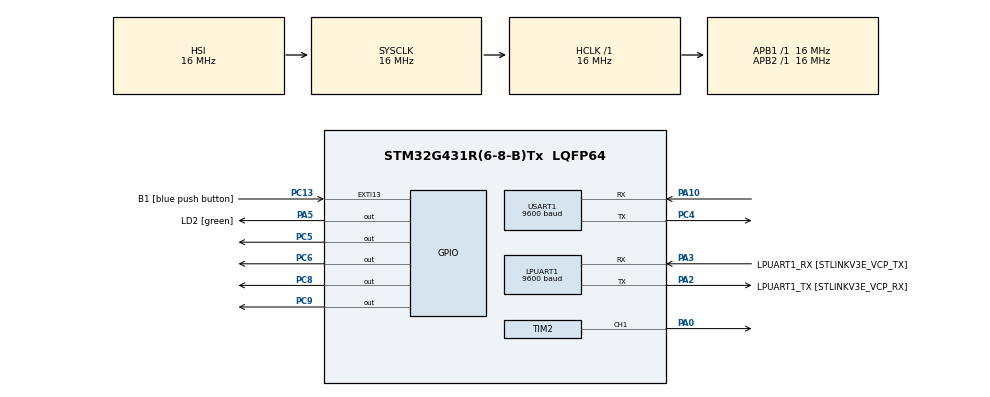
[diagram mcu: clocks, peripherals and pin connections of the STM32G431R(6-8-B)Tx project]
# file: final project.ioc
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LPUART1.BaudRate=9600
LPUART1.WordLength=UART_WORDLENGTH_8B
Mcu.Family=STM32G4
Mcu.Name=STM32G431R(6-8-B)Tx
Mcu.Package=LQFP64
NVIC.PriorityGroup=NVIC_PRIORITYGROUP_4
PA0.Signal=S_TIM2_CH1
PA10.Mode=Asynchronous
PA10.Signal=USART1_RX
PA13.GPIO_Label=T_SWDIO
PA13.Mode=Serial_Wire
PA13.Signal=SYS_JTMS-SWDIO
PA14.GPIO_Label=T_SWCLK
PA14.Mode=Serial_Wire
PA14.Signal=SYS_JTCK-SWCLK
PA2.GPIO_Label=LPUART1_TX [STLINKV3E_VCP_RX]
PA2.Mode=Asynchronous
PA2.Signal=LPUART1_TX
PA3.GPIO_Label=LPUART1_RX [STLINKV3E_VCP_TX]
PA3.Mode=Asynchronous
PA3.Signal=LPUART1_RX
PA5.GPIO_Label=LD2 [green]
PA5.Signal=GPIO_Output
PB3.GPIO_Label=T_SWO
PB3.Signal=SYS_JTDO-SWO
PC13.GPIO_Label=B1 [blue push button]
PC13.Signal=GPXTI13
PC14-OSC32_IN.Mode=LSE-External-Oscillator
PC14-OSC32_IN.Signal=RCC_OSC32_IN
PC15-OSC32_OUT.Mode=LSE-External-Oscillator
PC15-OSC32_OUT.Signal=RCC_OSC32_OUT
PC4.Mode=Asynchronous
PC4.Signal=USART1_TX
PC5.Signal=GPIO_Output
PC6.Signal=GPIO_Output
PC8.Signal=GPIO_Output
PC9.Signal=GPIO_Output
PF0-OSC_IN.Mode=HSE-External-Oscillator
PF0-OSC_IN.Signal=RCC_OSC_IN
PF1-OSC_OUT.Mode=HSE-External-Oscillator
PF1-OSC_OUT.Signal=RCC_OSC_OUT
ProjectManager.HeapSize=0x200
ProjectManager.StackSize=0x400
ProjectManager.TargetToolchain=STM32CubeIDE
RCC.ADC12Freq_Value=16000000
RCC.AHBFreq_Value=16000000
RCC.APB1Freq_Value=16000000
RCC.APB1TimFreq_Value=16000000
RCC.APB2Freq_Value=16000000
RCC.APB2TimFreq_Value=16000000
RCC.CortexFreq_Value=16000000
RCC.EXTERNAL_CLOCK_VALUE=12288000
RCC.HCLKFreq_Value=16000000
RCC.HSE_VALUE=24000000
RCC.HSI48_VALUE=48000000
RCC.HSI_VALUE=16000000
RCC.PLLM=RCC_PLLM_DIV4
RCC.PLLN=85
RCC.RTCClockSelection=RCC_RTCCLKSOURCE_LSE
RCC.SYSCLKFreq_VALUE=16000000
RCC.USBFreq_Value=170000000
RCC.VCOOutputFreq_Value=340000000
SH.S_TIM2_CH1.0=TIM2_CH1,PWM Generation1 CH1
TIM2.Channel-PWM\ Generation1\ CH1=TIM_CHANNEL_1
TIM2.PeriodNoDither=100
TIM2.Prescaler=16000-1
USART1.BaudRate=9600
USART1.VirtualMode-Asynchronous=VM_ASYNC
VP_SYS_VS_DBSignals.Mode=DisableDeadBatterySignals
VP_TIM2_VS_ClockSourceINT.Mode=Internal
board=NUCLEO-G431RB

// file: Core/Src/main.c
/* USER CODE BEGIN Header */
/**
  ******************************************************************************
  * @file           : main.c
  * @brief          : Main program body
  ******************************************************************************
  * @attention
  *
  * Copyright (c) 2023 STMicroelectronics.
  * All rights reserved.
  *
  * This software is licensed under terms that can be found in the LICENSE file
  * in the root directory of this software component.
  * If no LICENSE file comes with this software, it is provided AS-IS.
  *
  ******************************************************************************
  */
/* USER CODE END Header */
#include "main.h"

UART_HandleTypeDef hlpuart1;
UART_HandleTypeDef huart1;

TIM_HandleTypeDef htim2;

void SystemClock_Config(void);
static void MX_GPIO_Init(void);
static void MX_LPUART1_UART_Init(void);
static void MX_TIM2_Init(void);
static void MX_USART1_UART_Init(void);

int main(void)
{
  /* USER CODE BEGIN 1 */
char c;
  /* USER CODE END 1 */

  /* MCU Configuration--------------------------------------------------------*/

  /* Reset of all peripherals, Initializes the Flash interface and the Systick. */
  HAL_Init();

  /* Configure the system clock */
  SystemClock_Config();

  /* Initialize all configured peripherals */
  MX_GPIO_Init();
  MX_LPUART1_UART_Init();
  MX_TIM2_Init();
  MX_USART1_UART_Init();

  /* Infinite loop */
  while (1)
  {
	  HAL_UART_Receive(&huart1,&c,1,2000);
	  HAL_TIM_PWM_Start(&htim2,TIM_CHANNEL_1);
	  switch (c)
	  {

/////////////////////////////////////////////////////MOTOR 1////////////////////////////////////////////////
	  case 'A':
	  HAL_GPIO_WritePin(GPIOC,GPIO_PIN_8,GPIO_PIN_SET);                      //FORWARD MOTOR1
	  HAL_GPIO_WritePin(GPIOC,GPIO_PIN_9,GPIO_PIN_RESET);

	  break;

	  case 'B':
	  HAL_GPIO_WritePin(GPIOC,GPIO_PIN_8,GPIO_PIN_RESET);
	  HAL_GPIO_WritePin(GPIOC,GPIO_PIN_9,GPIO_PIN_SET); //REVERSE MOTOR1
	  break;

/////////////////////////////////////////////////////////MOTOR 2///////////////////////////////////////////////

	  case 'C':
	  HAL_GPIO_WritePin(GPIOC,GPIO_PIN_5,GPIO_PIN_SET);
	  HAL_GPIO_WritePin(GPIOC,GPIO_PIN_6,GPIO_PIN_RESET);//FORWARD MOTOR2
	  break;
	  case 'D':
	  HAL_GPIO_WritePin(GPIOC,GPIO_PIN_5,GPIO_PIN_RESET);
	  HAL_GPIO_WritePin(GPIOC,GPIO_PIN_6,GPIO_PIN_SET);//REVERSE MOTOR2
	  break;

///////////////////////////////////////////////////BRAKES/////////////////////////////////////////////////////
	  case 'F':
	  HAL_GPIO_WritePin(GPIOC,GPIO_PIN_5,GPIO_PIN_RESET);
	  HAL_GPIO_WritePin(GPIOC,GPIO_PIN_6,GPIO_PIN_RESET);//STOP MOTOR2
	  break;

	  case 'S':
	  HAL_GPIO_WritePin(GPIOC,GPIO_PIN_8,GPIO_PIN_RESET);
	  HAL_GPIO_WritePin(GPIOC,GPIO_PIN_9,GPIO_PIN_RESET);//STOP MOTOR1
	  break;

	  case 'X':
	  HAL_GPIO_WritePin(GPIOC,GPIO_PIN_5,GPIO_PIN_RESET);
	  HAL_GPIO_WritePin(GPIOC,GPIO_PIN_6,GPIO_PIN_RESET);
	  HAL_GPIO_WritePin(GPIOC,GPIO_PIN_8,GPIO_PIN_RESET); ///STOP ALL MOTOR
	  HAL_GPIO_WritePin(GPIOC,GPIO_PIN_9,GPIO_PIN_RESET);
	  break;

///////////////////////////////////////////////////////////SPEED CONTROL//////////////////////////////////////////////////

	  case '0':
		  TIM2->CCR1=10;
	  break;

	  case '1':
		  TIM2->CCR1=20;
	  break;
	  case '2':
		  TIM2->CCR1=30;
	  break;

	  case '3':
		  TIM2->CCR1=40;
	  break;
	  case '4':
		  TIM2->CCR1=50;
	  break;

	  case '5':
		  TIM2->CCR1=60;
	  break;
	  case '6':
		  TIM2->CCR1=70;
	  break;

	  case '7':
		  TIM2->CCR1=80;
	  break;
	  case '8':
		  TIM2->CCR1=90;
	  break;

	  case '9':
		  TIM2->CCR1=100;
	  break;

/////////////////////////////////////////////////////////////////////////////////////////////////////////////////
	  }
  }
}

void SystemClock_Config(void)
{
  RCC_OscInitTypeDef RCC_OscInitStruct = {0};
  RCC_ClkInitTypeDef RCC_ClkInitStruct = {0};

  /** Configure the main internal regulator output voltage
  */
  HAL_PWREx_ControlVoltageScaling(PWR_REGULATOR_VOLTAGE_SCALE1);

  /** Initializes the RCC Oscillators according to the specified parameters
  * in the RCC_OscInitTypeDef structure.
  */
  RCC_OscInitStruct.OscillatorType = RCC_OSCILLATORTYPE_HSI;
  RCC_OscInitStruct.HSIState = RCC_HSI_ON;
  RCC_OscInitStruct.HSICalibrationValue = RCC_HSICALIBRATION_DEFAULT;
  RCC_OscInitStruct.PLL.PLLState = RCC_PLL_NONE;
  if (HAL_RCC_OscConfig(&RCC_OscInitStruct) != HAL_OK)
  {
    Error_Handler();
  }

  /** Initializes the CPU, AHB and APB buses clocks
  */
  RCC_ClkInitStruct.ClockType = RCC_CLOCKTYPE_HCLK|RCC_CLOCKTYPE_SYSCLK
                              |RCC_CLOCKTYPE_PCLK1|RCC_CLOCKTYPE_PCLK2;
  RCC_ClkInitStruct.SYSCLKSource = RCC_SYSCLKSOURCE_HSI;
  RCC_ClkInitStruct.AHBCLKDivider = RCC_SYSCLK_DIV1;
  RCC_ClkInitStruct.APB1CLKDivider = RCC_HCLK_DIV1;
  RCC_ClkInitStruct.APB2CLKDivider = RCC_HCLK_DIV1;

  if (HAL_RCC_ClockConfig(&RCC_ClkInitStruct, FLASH_LATENCY_0) != HAL_OK)
  {
    Error_Handler();
  }
}

static void MX_LPUART1_UART_Init(void)
{

  hlpuart1.Instance = LPUART1;
  hlpuart1.Init.BaudRate = 9600;
  hlpuart1.Init.WordLength = UART_WORDLENGTH_8B;
  hlpuart1.Init.StopBits = UART_STOPBITS_1;
  hlpuart1.Init.Parity = UART_PARITY_NONE;
  hlpuart1.Init.Mode = UART_MODE_TX_RX;
  hlpuart1.Init.HwFlowCtl = UART_HWCONTROL_NONE;
  hlpuart1.Init.OneBitSampling = UART_ONE_BIT_SAMPLE_DISABLE;
  hlpuart1.Init.ClockPrescaler = UART_PRESCALER_DIV1;
  hlpuart1.AdvancedInit.AdvFeatureInit = UART_ADVFEATURE_NO_INIT;
  if (HAL_UART_Init(&hlpuart1) != HAL_OK)
  {
    Error_Handler();
  }
  if (HAL_UARTEx_SetTxFifoThreshold(&hlpuart1, UART_TXFIFO_THRESHOLD_1_8) != HAL_OK)
  {
    Error_Handler();
  }
  if (HAL_UARTEx_SetRxFifoThreshold(&hlpuart1, UART_RXFIFO_THRESHOLD_1_8) != HAL_OK)
  {
    Error_Handler();
  }
  if (HAL_UARTEx_DisableFifoMode(&hlpuart1) != HAL_OK)
  {
    Error_Handler();
  }

}

static void MX_USART1_UART_Init(void)
{

  huart1.Instance = USART1;
  huart1.Init.BaudRate = 9600;
  huart1.Init.WordLength = UART_WORDLENGTH_8B;
  huart1.Init.StopBits = UART_STOPBITS_1;
  huart1.Init.Parity = UART_PARITY_NONE;
  huart1.Init.Mode = UART_MODE_TX_RX;
  huart1.Init.HwFlowCtl = UART_HWCONTROL_NONE;
  huart1.Init.OverSampling = UART_OVERSAMPLING_16;
  huart1.Init.OneBitSampling = UART_ONE_BIT_SAMPLE_DISABLE;
  huart1.Init.ClockPrescaler = UART_PRESCALER_DIV1;
  huart1.AdvancedInit.AdvFeatureInit = UART_ADVFEATURE_NO_INIT;
  if (HAL_UART_Init(&huart1) != HAL_OK)
  {
    Error_Handler();
  }
  if (HAL_UARTEx_SetTxFifoThreshold(&huart1, UART_TXFIFO_THRESHOLD_1_8) != HAL_OK)
  {
    Error_Handler();
  }
  if (HAL_UARTEx_SetRxFifoThreshold(&huart1, UART_RXFIFO_THRESHOLD_1_8) != HAL_OK)
  {
    Error_Handler();
  }
  if (HAL_UARTEx_DisableFifoMode(&huart1) != HAL_OK)
  {
    Error_Handler();
  }

}

static void MX_TIM2_Init(void)
{

  TIM_ClockConfigTypeDef sClockSourceConfig = {0};
  TIM_MasterConfigTypeDef sMasterConfig = {0};
  TIM_OC_InitTypeDef sConfigOC = {0};

  htim2.Instance = TIM2;
  htim2.Init.Prescaler = 16000-1;
  htim2.Init.CounterMode = TIM_COUNTERMODE_UP;
  htim2.Init.Period = 100;
  htim2.Init.ClockDivision = TIM_CLOCKDIVISION_DIV1;
  htim2.Init.AutoReloadPreload = TIM_AUTORELOAD_PRELOAD_DISABLE;
  if (HAL_TIM_Base_Init(&htim2) != HAL_OK)
  {
    Error_Handler();
  }
  sClockSourceConfig.ClockSource = TIM_CLOCKSOURCE_INTERNAL;
  if (HAL_TIM_ConfigClockSource(&htim2, &sClockSourceConfig) != HAL_OK)
  {
    Error_Handler();
  }
  if (HAL_TIM_PWM_Init(&htim2) != HAL_OK)
  {
    Error_Handler();
  }
  sMasterConfig.MasterOutputTrigger = TIM_TRGO_RESET;
  sMasterConfig.MasterSlaveMode = TIM_MASTERSLAVEMODE_DISABLE;
  if (HAL_TIMEx_MasterConfigSynchronization(&htim2, &sMasterConfig) != HAL_OK)
  {
    Error_Handler();
  }
  sConfigOC.OCMode = TIM_OCMODE_PWM1;
  sConfigOC.Pulse = 0;
  sConfigOC.OCPolarity = TIM_OCPOLARITY_HIGH;
  sConfigOC.OCFastMode = TIM_OCFAST_DISABLE;
  if (HAL_TIM_PWM_ConfigChannel(&htim2, &sConfigOC, TIM_CHANNEL_1) != HAL_OK)
  {
    Error_Handler();
  }
  HAL_TIM_MspPostInit(&htim2);

}

static void MX_GPIO_Init(void)
{
  GPIO_InitTypeDef GPIO_InitStruct = {0};

  /* GPIO Ports Clock Enable */
  __HAL_RCC_GPIOC_CLK_ENABLE();
  __HAL_RCC_GPIOF_CLK_ENABLE();
  __HAL_RCC_GPIOA_CLK_ENABLE();
  __HAL_RCC_GPIOB_CLK_ENABLE();

  /*Configure GPIO pin Output Level */
  HAL_GPIO_WritePin(LD2_GPIO_Port, LD2_Pin, GPIO_PIN_RESET);

  /*Configure GPIO pin Output Level */
  HAL_GPIO_WritePin(GPIOC, GPIO_PIN_5|GPIO_PIN_6|GPIO_PIN_8|GPIO_PIN_9, GPIO_PIN_RESET);

  /*Configure GPIO pin : B1_Pin */
  GPIO_InitStruct.Pin = B1_Pin;
  GPIO_InitStruct.Mode = GPIO_MODE_IT_RISING;
  GPIO_InitStruct.Pull = GPIO_NOPULL;
  HAL_GPIO_Init(B1_GPIO_Port, &GPIO_InitStruct);

  /*Configure GPIO pin : LD2_Pin */
  GPIO_InitStruct.Pin = LD2_Pin;
  GPIO_InitStruct.Mode = GPIO_MODE_OUTPUT_PP;
  GPIO_InitStruct.Pull = GPIO_NOPULL;
  GPIO_InitStruct.Speed = GPIO_SPEED_FREQ_LOW;
  HAL_GPIO_Init(LD2_GPIO_Port, &GPIO_InitStruct);

  /*Configure GPIO pins : PC5 PC6 PC8 PC9 */
  GPIO_InitStruct.Pin = GPIO_PIN_5|GPIO_PIN_6|GPIO_PIN_8|GPIO_PIN_9;
  GPIO_InitStruct.Mode = GPIO_MODE_OUTPUT_PP;
  GPIO_InitStruct.Pull = GPIO_NOPULL;
  GPIO_InitStruct.Speed = GPIO_SPEED_FREQ_LOW;
  HAL_GPIO_Init(GPIOC, &GPIO_InitStruct);

}

void Error_Handler(void)
{
  __disable_irq();
  while (1)
  {
  }
}
